# STM32F769xx register map
File version: 1.0
Registers are 32-bit, access not given, reset 0x0 unless marked. A register's access mark holds for its fields unless they carry their own. Offsets are from the block's base; [hi:lo] are bit positions; {n}, {i} and the like mark numbered series.

## SAI1
Base 0x40015800
Same registers: SAI2 0x40015C00
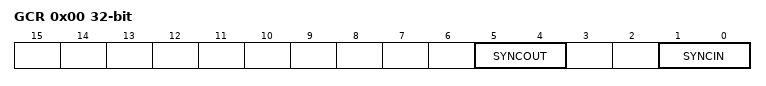
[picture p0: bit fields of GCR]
0x00 GCR
  [5:4] SYNCOUT, [1:0] SYNCIN
0x04 CR1A
0x08 CR2A
0x10 FRCRA
0x1C SLOTRA
0x24 CR1B
0x28 CR2B
0x2C IMRA
0x30 FRCRB
0x3C SLOTRB
0x40 SRA
0x4C IMRB
0x58 CLRFRA
0x60 SRB
0x74 DRA
0x78 CLRFRB
0x94 DRB

## LTDC
Base 0x40016800
0x08 SSCR
  [31] HSPOL, [30] VSPOL, [29] DEPOL, [28] PCPOL, [27:16] HSW, [27:16] AHBP, [27:16] AAW, [27:16] TOTALW, [16] DEN, [23:16] BCRED, [31:16] CXPOS, [14:12] DRW, [10:8] DGW, [15:8] BCGREEN, [6:4] DBW, [3] RRIE, [3] RRIF, [3] CRRIF, [3] HSYNCS, [2] TERRIE, [2] TERRIF, [2] CTERRIF, [2] VSYNCS, [1] VBR, [1] FUIE, [1] FUIF, [1] CFUIF, [1] HDES, [10:0] VSH, [10:0] AVBP, [10:0] AAH, [10:0] TOTALH, [0] LTDCEN, [0] IMR, [7:0] BCBLUE, [0] LIE, [0] LIF, [0] CLIF, [10:0] LIPOS, [15:0] CYPOS, [0] VDES
0x0C BPCR
0x10 AWCR
0x14 TWCR
0x18 GCR
0x24 SRCR
0x2C BCCR
0x34 IER
0x38 ISR
0x3C ICR
0x40 LIPCR
0x44 CPSR
0x48 CDSR
0x84 CR1
0x88 WHPCR1
0x90 WVPCR1
0x9C CKCR1
0xAC PFCR1
0xC0 CACR1
0xD8 DCCR1
0xF4 BFCR1
0x104 CR2
0x108 WHPCR2
0x110 WVPCR2
0x11C CFBAR1
0x11C CKCR2
0x12C PFCR2
0x140 CACR2
0x148 CFBLR1
0x158 DCCR2
0x174 BFCR2
0x178 CFBLNR1
0x19C CFBAR2
0x1B8 CLUTWR1
0x1C8 CFBLR2
0x1F8 CFBLNR2
0x238 CLUTWR2

## MDIOS
Base 0x40017800
0x00 CR
  [12:8] PORT_ADDRESS, [7] DPC, [3] EIE, [2] RDIE, [2] TERF, [2] CTERF, [1] WRIE, [1] SERF, [1] CSERF, [0] EN, [31:0] WRF, [31:0] CWRF, [31:0] RDF, [31:0] CRDF, [0] PERF, [0] CPERF
0x04 WRFR
0x08 CWRFR
0x0C RDFR
0x10 CRDFR
0x14 SR
0x18 CLRFR
{0x100+4i} DINR{i} (i=0..31)
{0x180+4i} DOUTR{i} (i=0..31)

## GPIOA
Base 0x40020000
Same registers: GPIOB 0x40020400, GPIOC 0x40020800, GPIOD 0x40020C00, GPIOE 0x40021000, GPIOF 0x40021400, GPIOG 0x40021800, GPIOH 0x40021C00, GPIOI 0x40022000, GPIOJ 0x40022400, GPIOK 0x40022800
0x00 MODER
  [n+16] BR{n} (n=0..15), [2n+1:2n] MODER{n} (n=0..15), [2n+1:2n] OSPEEDR{n} (n=0..15), [2n+1:2n] PUPDR{n} (n=0..15), [4n+3:4n] AFRL{n} (n=0..7), [4n+3:4n] AFRH{n} (n=0..7), [16] LCKK, [n] OT{n} (n=0..15), [n] ID{n} (n=0..15), [n] OD{n} (n=0..15), [n] BS{n} (n=0..15), [n] LCK{n} (n=0..15)
0x04 OTYPER
0x08 OSPEEDR
0x0C PUPDR
0x10 IDR
0x14 ODR
0x18 BSRR
0x1C LCKR
0x20 AFR.0
0x24 AFR.1

## CRC
Base 0x40023000
0x00 DR
  [7] REV_OUT, [6:5] REV_IN, [4:3] POLYSIZE, [31:0] DR, [7:0] IDR, [0] RESET, [31:0] INIT, [31:0] POL
0x04 IDR 8-bit
0x08 CR
0x10 INIT
0x14 POL

## FLASH
Base 0x40023C00
0x00 ACR
  [31] LOCK, [31] IWDG_STOP, [30] IWDG_STDBY, [29] nDBANK, [28] nDBOOT, [25] ERRIE, [24] EOPIE, [16] BSY, [16] STRT, [27:16] nWRP, [31:16] BOOT_ADD1, [15] MER2, [11] ARTRST, [9] ARTEN, [8] PRFTEN, [9:8] PSIZE, [15:8] RDP, [7] ERSERR, [7] nRST_STDBY, [6] PGPERR, [6] nRST_STOP, [5] PGAERR, [5] IWDG_SW, [4] WRPERR, [4] WWDG_SW, [7:3] SNB, [2] MER, [3:2] BOR_LEV, [1] OPERR, [1] SER, [1] OPTSTRT, [3:0] LATENCY, [0] EOP, [0] PG, [0] OPTLOCK, [15:0] BOOT_ADD0
0x04 KEYR
0x08 OPTKEYR
0x0C SR
0x10 CR
0x14 OPTCR
0x18 OPTCR1

## DMA1
Base 0x40026000
Same registers: DMA2 0x40026400
0x00 LISR
  [27] TCIF3, [27] TCIF7, [27] CTCIF3, [27] CTCIF7, [26] HTIF3, [26] HTIF7, [26] CHTIF3, [26] CHTIF7, [25] TEIF3, [25] TEIF7, [25] CTEIF3, [25] CTEIF7, [24] DMEIF3, [24] DMEIF7, [24] CDMEIF3, [24] CDMEIF7, [22] FEIF3, [22] FEIF7, [22] CFEIF3, [22] CFEIF7, [21] TCIF2, [21] TCIF6, [21] CTCIF2, [21] CTCIF6, [20] HTIF2, [20] HTIF6, [20] CHTIF2, [20] CHTIF6, [19] TEIF2, [19] TEIF6, [19] CTEIF2, [19] CTEIF6, [18] DMEIF2, [18] DMEIF6, [18] CDMEIF2, [18] CDMEIF6, [16] FEIF2, [16] FEIF6, [16] CFEIF2, [16] CFEIF6, [11] TCIF1, [11] TCIF5, [11] CTCIF1, [11] CTCIF5, [10] HTIF1, [10] HTIF5, [10] CHTIF1, [10] CHTIF5, [9] TEIF1, [9] TEIF5, [9] CTEIF1, [9] CTEIF5, [8] DMEIF1, [8] DMEIF5, [8] CDMEIF1, [8] CDMEIF5, [6] FEIF1, [6] FEIF5, [6] CFEIF1, [6] CFEIF5, [5] TCIF0, [5] TCIF4, [5] CTCIF0, [5] CTCIF4, [4] HTIF0, [4] HTIF4, [4] CHTIF0, [4] CHTIF4, [3] TEIF0, [3] TEIF4, [3] CTEIF0, [3] CTEIF4, [2] DMEIF0, [2] DMEIF4, [2] CDMEIF0, [2] CDMEIF4, [0] FEIF0, [0] FEIF4, [0] CFEIF0, [0] CFEIF4
0x04 HISR
0x08 LIFCR
0x0C HIFCR
{0x10+0x18*i} CR{i} (i=0..7)
{0x14+0x18*i} NDTR{i} (i=0..7)
{0x1C+0x18*i} PAR{i} (i=0..7)
{0x28+0x18*i} M0AR{i} (i=0..7)
{0x38+0x18*i} M1AR{i} (i=0..7)
{0x4C+0x18*i} FCR{i} (i=0..7)
